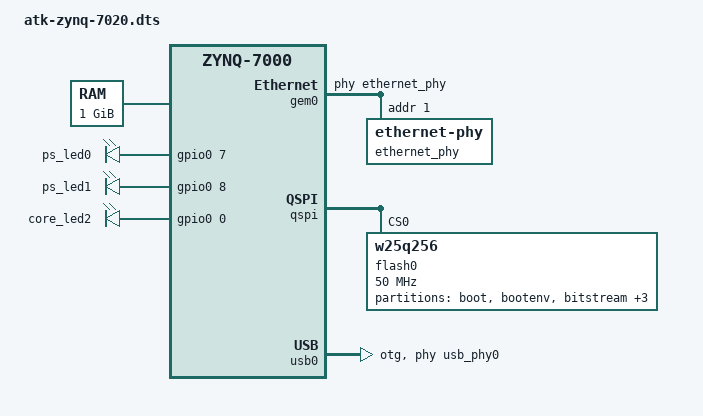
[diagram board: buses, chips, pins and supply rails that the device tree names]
/*
 * CAUTION: This file is automatically generated by Xilinx.
 * Version: HSI 
 * Today is: Fri Mar 27 20:03:45 2020
 */


/dts-v1/;
#include "zynq-7000.dtsi"
#include "7020-pcw.dtsi"
#include <dt-bindings/gpio/gpio.h>


/ {
	chosen {
		bootargs = "console=ttyPS0,115200 earlyprintk root=/dev/mmcblk0p2 rw rootwait";
		stdout-path = "serial0:115200n8";
	};
	aliases {
		ethernet0 = &gem0;
		serial0 = &uart0;
		spi0 = &qspi;
		mmc0 = &sdhci0;
		mmc1 = &sdhci1;
		usb0 = &usb0;
		gpio0 = &gpio0;
	};
	memory {
		device_type = "memory";
		reg = <0x0 0x40000000>;		// DDR size
	};

	gpio-leds {
		compatible = "gpio-leds";
		status = "okay";

		led@0 {
			label = "ps_led0";
			gpios = <&gpio0 7 GPIO_ACTIVE_HIGH>;
			default-state = "on";
		};

		led@1 {
			label = "ps_led1";
			gpios = <&gpio0 8 GPIO_ACTIVE_HIGH>;
			default-state = "on";
		};

		led@2 {
			label = "core_led2";
			gpios = <&gpio0 0 GPIO_ACTIVE_HIGH>;
			default-state = "on";
		};
	};

	usb_phy0: phy0@e0002000 {
		compatible = "ulpi-phy";
		#phy-cells = <0>;
		reg = <0xe0002000 0x1000>;
		view-port = <0x0170>;
		drv-vbus;
	};

	amba_pl: amba_pl {
		#address-cells = <1>;
		#size-cells = <1>;
		compatible = "simple-bus";
		ranges ;

		axi_gpio: gpio@41200000 {
			#gpio-cells = <3>;
			clock-names = "s_axi_aclk";
			clocks = <&clkc 15>;
			compatible = "xlnx,axi-gpio-2.0", "xlnx,xps-gpio-1.00.a";
			gpio-controller ;
			reg = <0x41200000 0x10000>;
			xlnx,all-inputs = <0x0>;
			xlnx,all-inputs-2 = <0x0>;
			xlnx,all-outputs = <0x0>;
			xlnx,all-outputs-2 = <0x0>;
			xlnx,dout-default = <0x00000000>;
			xlnx,dout-default-2 = <0x00000000>;
			xlnx,gpio-width = <0x3>;
			xlnx,gpio2-width = <0x20>;
			xlnx,interrupt-present = <0x0>;
			xlnx,is-dual = <0x0>;
			xlnx,tri-default = <0xFFFFFFFF>;
			xlnx,tri-default-2 = <0xFFFFFFFF>;
		};
	};
};

&gem0 {
	phy-handle = <&ethernet_phy>;
	local-mac-address = [00 0a 35 00 1e 53];

	ethernet_phy: ethernet-phy@1 {          /* rtl8211e */
		reg = <1>;
		device_type = "ethernet-phy";
	};
};

&sdhci0 {
	u-boot,dm-pre-reloc;
};

&uart0 {
	u-boot,dm-pre-reloc;
};

&qspi {
	u-boot,dm-pre-reloc;
	#address-cells = <1>;
	#size-cells = <0>;
	flash0: flash@0 {
		compatible = "w25q256";
		reg = <0x0>;
		#address-cells = <1>;
		#size-cells = <1>;
		spi-max-frequency = <50000000>;
		partition@0x00000000 {
			label = "boot";
			reg = <0x00000000 0x00100000>;
		};
		partition@0x00100000 {
			label = "bootenv";
			reg = <0x00100000 0x00020000>;
		};
		partition@0x00120000 {
			label = "bitstream";
			reg = <0x00120000 0x00400000>;
		};
		partition@0x00520000 {
			label = "device-tree";
			reg = <0x00520000 0x00020000>;
		};
		partition@0x00540000 {
			label = "kernel";
			reg = <0x00540000 0x00500000>;
		};
		partition@0x00A40000 {
			label = "space";
			reg = <0x00A40000 0x00000000>;
		};
	};
};

&usb0 {
	dr_mode = "otg";
	usb-phy = <&usb_phy0>;
};
